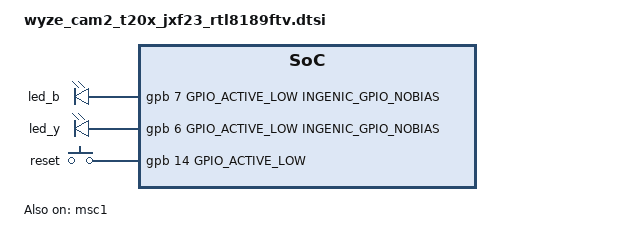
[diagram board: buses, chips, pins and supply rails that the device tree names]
// Wyze Cam v2 (T20X, JXF23, RTL8189FTV) per-board GPIO definitions.
// Injected into the kernel 4.4+ device tree; ignored on 3.10.

#include <dt-bindings/gpio/gpio.h>
#include <dt-bindings/input/input.h>
#include <dt-bindings/pinctrl/ingenic-pinctrl.h>

/ {
	gpio-leds {
		compatible = "gpio-leds";

		led_b {
			label = "led_b";
			gpios = <&gpb 7 GPIO_ACTIVE_LOW INGENIC_GPIO_NOBIAS>;
			default-state = "off";
		};

		led_y {
			label = "led_y";
			gpios = <&gpb 6 GPIO_ACTIVE_LOW INGENIC_GPIO_NOBIAS>;
			default-state = "off";
		};
	};
};

/* Card detect; the family tree carries the reference pin. */
&msc0 {
	ingenic,cd-gpios = <&gpb 11 GPIO_ACTIVE_LOW INGENIC_GPIO_PULLUP>;
};

/* SDIO WiFi; the T20 wires MSC1 to PC2-7. */
&msc1 {
	status = "okay";
	pinctrl-names = "default";
	pinctrl-0 = <&msc1_pc>;
	bus-width = <4>;
	max-frequency = <24000000>;
	ingenic,sdio_clk = <1>;
	non-removable;
};

&pinctrl {
	msc1_pc: msc1-pc {
		function = "mmc1";
		groups = "mmc1-pc-1bit", "mmc1-pc-4bit";
	};
};

/ {
	gpio-keys {
		compatible = "gpio-keys";
		label = "gpio-keys";

		reset {
			label = "reset";
			linux,code = <KEY_ENTER>;
			gpios = <&gpb 14 GPIO_ACTIVE_LOW INGENIC_GPIO_PULLUP>;
		};
	};
};
